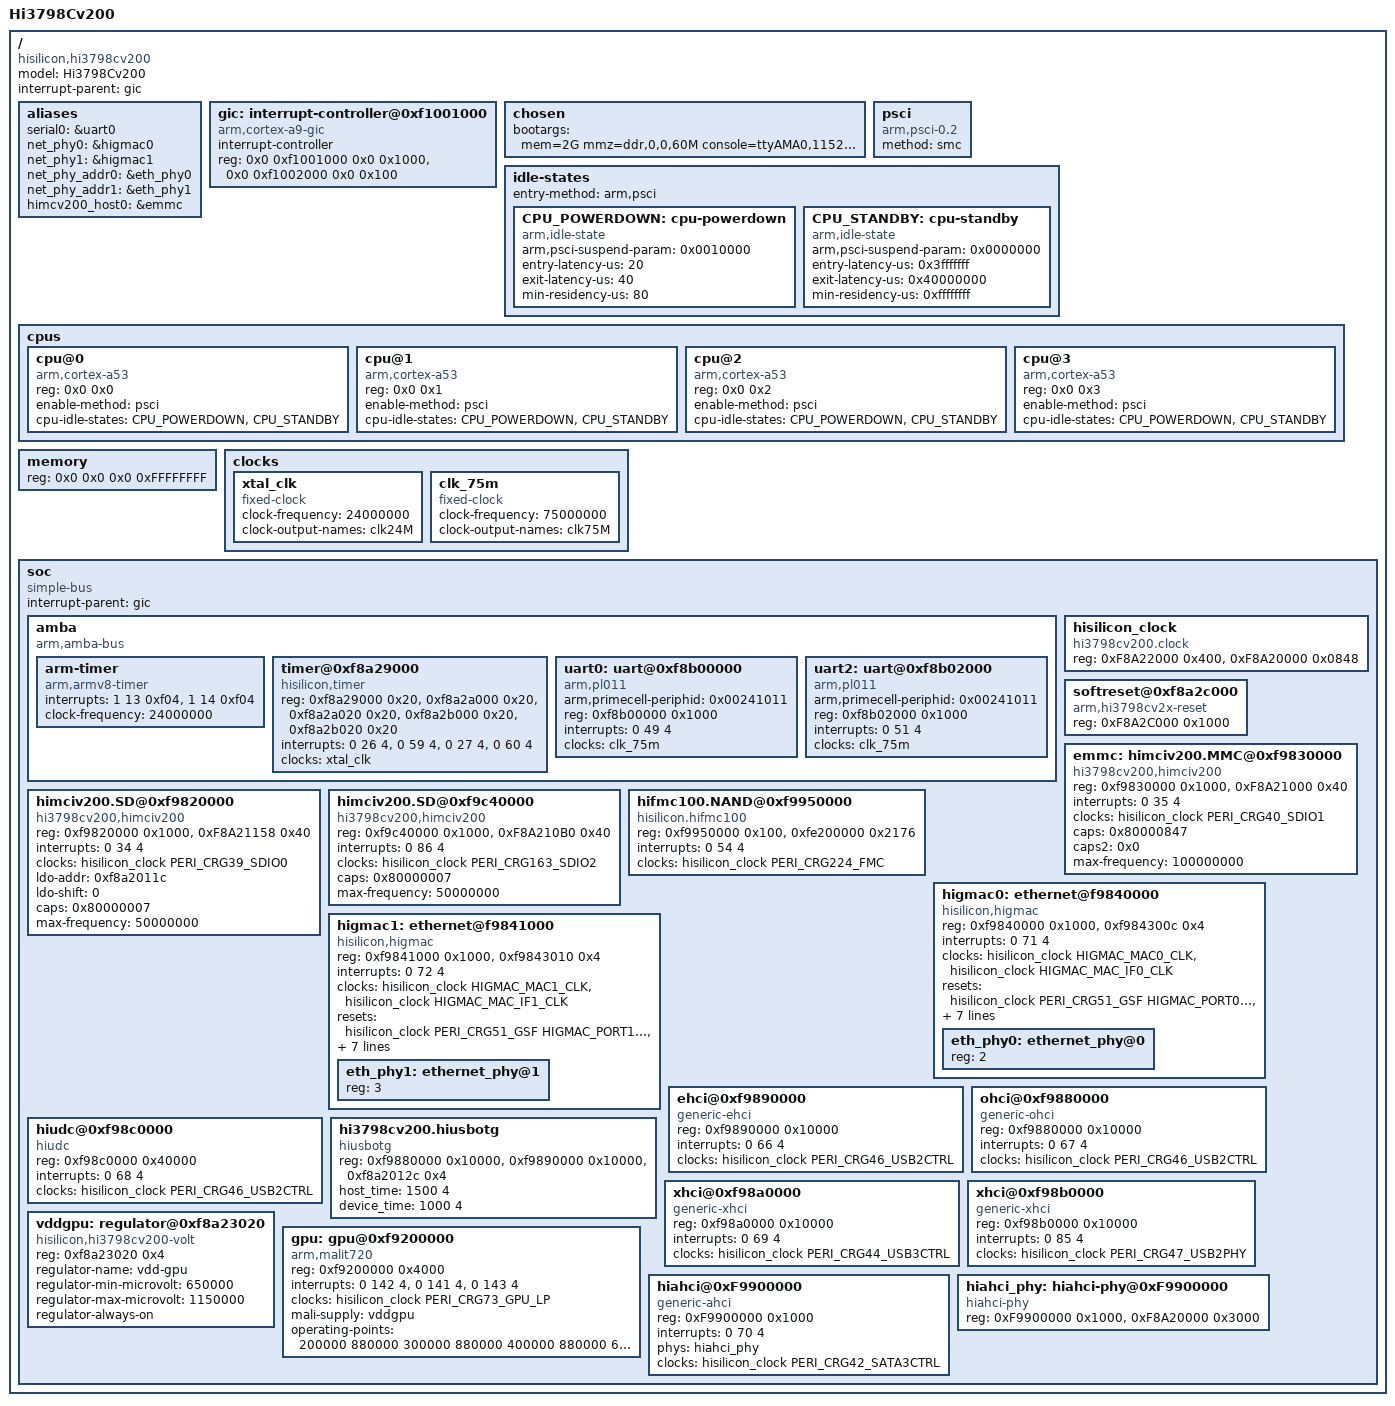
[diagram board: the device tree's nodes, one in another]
/*
 * Copyright (c) 2013 Linaro Ltd.
 * Copyright (c) 2013 Hisilicon Limited.
 *
 *  This program is free software; you can redistribute it and/or modify
 *  it under the terms of the GNU General Public License version 2 as
 *  publishhed by the Free Software Foundation.
 */

/dts-v1/;
/memreserve/ 0x00000000 0x00010000;
/* reserved for warmreset */
/memreserve/ 0xfff0000 0x00100000;
/* reserved for arm trustedfirmware */
/memreserve/ 0x4800000 0x00200000;

#include <dt-bindings/clock/hi3798cv200-clock.h>

/ {
	model = "Hi3798Cv200";
	compatible = "hisilicon,hi3798cv200";
	#address-cells = <2>;
	#size-cells = <2>;

	interrupt-parent = <&gic>;

	aliases {
		serial0 = &uart0;
		net_phy0 = &higmac0;
		net_phy1 = &higmac1;
		net_phy_addr0 = &eth_phy0;
		net_phy_addr1 = &eth_phy1;
		himcv200_host0 = &emmc;
	};

	gic: interrupt-controller@0xf1001000 {
		compatible = "arm,cortex-a9-gic"; /* TODO: maybe cortex-a53-gic in new kernel version */
		#interrupt-cells = <3>;
		#address-cells = <0>;
		interrupt-controller;
		/* gic dist base, gic cpu base */
		reg = <0x0 0xf1001000 0x0 0x1000>, <0x0 0xf1002000 0x0 0x100>;
	};

	chosen {
		bootargs = "mem=2G mmz=ddr,0,0,60M console=ttyAMA0,115200 root=/dev/mmcblk0p7 rootfstype=ext4 rootwait rw blkdevparts=mmcblk0:2M(boot),4M(baseparam),4M(pqparam),4M(logo),8M(trustedcore),16M(kernel),256M(rootfs),-(others) earlycon=pl011,0xf8b00000";
	};

	psci {
		compatible = "arm,psci-0.2";
		method = "smc";
	};

	idle-states {
		entry-method = "arm,psci";

		CPU_POWERDOWN: cpu-powerdown {
		       compatible = "arm,idle-state";
		       arm,psci-suspend-param = <0x0010000>;
		       entry-latency-us = <20>;
		       exit-latency-us = <40>;
		       min-residency-us = <80>;
		};
		CPU_STANDBY: cpu-standby {
		     compatible = "arm,idle-state";
		     arm,psci-suspend-param = <0x0000000>;
		     entry-latency-us = <0x3fffffff>;
		     exit-latency-us = <0x40000000>;
		     min-residency-us = <0xffffffff>;
		};
	};

	cpus {
		#address-cells = <2>;
		#size-cells = <0>;

		cpu@0 {
			compatible = "arm,cortex-a53";
			device_type = "cpu";
			reg = <0x0 0x0>;
			enable-method = "psci";
			cpu-idle-states = <&CPU_POWERDOWN &CPU_STANDBY>;
		};

		cpu@1 {
			compatible = "arm,cortex-a53";
			device_type = "cpu";
			reg = <0x0 0x1>;
			enable-method = "psci";
			cpu-idle-states = <&CPU_POWERDOWN &CPU_STANDBY>;
		};
		cpu@2 {
			compatible = "arm,cortex-a53";
			device_type = "cpu";
			reg = <0x0 0x2>;
			enable-method = "psci";
			cpu-idle-states = <&CPU_POWERDOWN &CPU_STANDBY>;
		};
		cpu@3 {
			compatible = "arm,cortex-a53";
			device_type = "cpu";
			reg = <0x0 0x3>;
			enable-method = "psci";
			cpu-idle-states = <&CPU_POWERDOWN &CPU_STANDBY>;
		};

	};

	memory {
		device_type = "memory";

		reg = <0x0 0x0 0x0 0xFFFFFFFF>;
	};

	clocks {
		xtal_clk: xtal_clk {
			compatible = "fixed-clock";
			#clock-cells = <0>;
			clock-frequency = <24000000>;
			clock-output-names = "clk24M";
		};

		clk_75m: clk_75m{
			compatible = "fixed-clock";
			#clock-cells = <0>;
			clock-frequency = <75000000>;
			clock-output-names = "clk75M";
		};
	};

	soc {
		#address-cells = <1>;
		#size-cells = <1>;
		compatible = "simple-bus";
		device_type = "soc";
		interrupt-parent = <&gic>;
		ranges = <0x0 0x00000000 0x0 0xffffffff>;

		amba {
			compatible = "arm,amba-bus";
			#address-cells = <1>;
			#size-cells = <1>;

			ranges;

			arm-timer {
				compatible = "arm,armv8-timer";
				interrupts = <1 13 0xf04>,
					     <1 14 0xf04>;
				clock-frequency = <24000000>;
			};

			/*
			 * Used for clocksource and local timer
			 */
			timer@0xf8a29000 {
				compatible = "hisilicon,timer";
				reg = <0xf8a29000 0x20>, /* clocksource */
				      <0xf8a2a000 0x20>, /* local timer for each cpu */
				      <0xf8a2a020 0x20>,
				      <0xf8a2b000 0x20>,
				      <0xf8a2b020 0x20>;
				interrupts = <0 26 4>, /* irq of local timer */
					     <0 59 4>,
					     <0 27 4>,
					     <0 60 4>;
				clocks = <&xtal_clk>;
				clock-names = "apb_pclk";
			};

			uart0: uart@0xf8b00000 {
				compatible = "arm,pl011", "arm,primecell";
				arm,primecell-periphid = <0x00241011>;
				reg = <0xf8b00000 0x1000>;
				interrupts = <0 49 4>;
				clocks = <&clk_75m>;
				clock-names = "apb_pclk";
			};

			uart2: uart@0xf8b02000 {
				compatible = "arm,pl011", "arm,primecell";
				arm,primecell-periphid = <0x00241011>;
				reg = <0xf8b02000 0x1000>;
				interrupts = <0 51 4>;
				clocks = <&clk_75m>;
				clock-names = "apb_pclk";
			};
		};

		hisilicon_clock: hisilicon_clock {
			compatible = "hi3798cv200.clock","hisilicon,clock-reset";
			reg = <0xF8A22000 0x400>, <0xF8A20000 0x0848>;
			#clock-cells = <1>;
			#reset-cells = <2>;
		};

		softreset@0xf8a2c000 {
			compatible = "arm,hi3798cv2x-reset";
			reg = <0xF8A2C000 0x1000>;
		};

		emmc: himciv200.MMC@0xf9830000 {
			compatible = "hi3798cv200,himciv200";
			reg = <0xf9830000 0x1000>,<0xF8A21000 0x40>;
			interrupts = <0 35 4>;

			clocks = <&hisilicon_clock PERI_CRG40_SDIO1>;
			clock-names = "clk";

			caps = <0x80000847>;
			caps2 = <0x0>;
			max-frequency = <100000000>;
			status = "okay";
		};

		himciv200.SD@0xf9820000 {
			compatible = "hi3798cv200,himciv200";
			reg = <0xf9820000 0x1000>,<0xF8A21158 0x40>;
			interrupts = <0 34 4>;

			clocks = <&hisilicon_clock PERI_CRG39_SDIO0>;
			clock-names = "clk";

			ldo-addr  = <0xf8a2011c>;
			ldo-shift = <0>;

			caps = <0x80000007>;
			max-frequency = <50000000>;
			status = "okay";
		};

		himciv200.SD@0xf9c40000 {
			compatible = "hi3798cv200,himciv200";
			reg = <0xf9c40000 0x1000>,<0xF8A210B0 0x40>;
			interrupts = <0 86 4>;

			clocks = <&hisilicon_clock PERI_CRG163_SDIO2>;
			clock-names = "clk";

			caps = <0x80000007>;
			max-frequency = <50000000>;
			status = "okay";
		};

		hifmc100.NAND@0xf9950000 {
			compatible = "hisilicon.hifmc100";
			reg = <0xf9950000 0x100>, <0xfe200000 0x2176>;
			interrupts = <0 54 4>;

			clocks = <&hisilicon_clock PERI_CRG224_FMC>;
			clock-names = "clk";
		};

		higmac0: ethernet@f9840000 {
			compatible = "hisilicon,higmac";
			reg = <0xf9840000 0x1000>,<0xf984300c 0x4>;
			interrupts = <0 71 4>;

			clocks = <&hisilicon_clock HIGMAC_MAC0_CLK>,
					<&hisilicon_clock HIGMAC_MAC_IF0_CLK>;
			clock-names = "higmac_clk",
					"macif_clk";

			resets = <&hisilicon_clock PERI_CRG51_GSF HIGMAC_PORT0_RST_BIT>,
					<&hisilicon_clock PERI_CRG51_GSF HIGMAC_MACIF0_RST_BIT>,
					<&hisilicon_clock PERI_CRG51_GSF HIGMAC_PHY0_RST_BIT>;
			reset-names = "port_reset",
					"macif_reset",
					"phy_reset";

			#address-cells = <1>;
			#size-cells = <0>;

			mac-address = [00 00 00 00 00 00];

			phy-handle = <&eth_phy0>;
			phy-mode = "mii";
			phy-gpio-base = <0>;
			phy-gpio-bit = <0>;

			eth_phy0: ethernet_phy@0 {
				reg = <2>;
			};
		};

		higmac1: ethernet@f9841000 {
			compatible = "hisilicon,higmac";
			reg = <0xf9841000 0x1000>,<0xf9843010 0x4>;
			interrupts = <0 72 4>;

			clocks = <&hisilicon_clock HIGMAC_MAC1_CLK>,
					<&hisilicon_clock HIGMAC_MAC_IF1_CLK>;
			clock-names = "higmac_clk",
					"macif_clk";

			resets = <&hisilicon_clock PERI_CRG51_GSF HIGMAC_PORT1_RST_BIT>,
					<&hisilicon_clock PERI_CRG51_GSF HIGMAC_MACIF1_RST_BIT>,
					<&hisilicon_clock PERI_CRG51_GSF HIGMAC_PHY1_RST_BIT>;
			reset-names = "port_reset",
					"macif_reset",
					"phy_reset";

			#address-cells = <1>;
			#size-cells = <0>;

			mac-address = [00 00 00 00 00 00];

			phy-handle = <&eth_phy1>;
			phy-mode = "rgmii";
			phy-gpio-base = <0>;
			phy-gpio-bit = <0>;

			eth_phy1: ethernet_phy@1{
				reg = <3>;
			};
		};

		ehci@0xf9890000 {
			compatible = "generic-ehci";
			reg = <0xf9890000 0x10000>;
			interrupts = <0 66 4>;

			clocks = <&hisilicon_clock PERI_CRG46_USB2CTRL>;
			clock-names = "clk";
		};

		ohci@0xf9880000 {
			compatible = "generic-ohci";
			reg = <0xf9880000 0x10000>;
			interrupts = <0 67 4>;

			clocks = <&hisilicon_clock PERI_CRG46_USB2CTRL>;
			clock-names = "clk";
		};

		hiudc@0xf98c0000 {
			compatible = "hiudc";
			reg = <0xf98c0000 0x40000>;
			interrupts = <0 68 4>;

			clocks = <&hisilicon_clock PERI_CRG46_USB2CTRL>;
			clock-names = "clk";
		};

		hi3798cv200.hiusbotg {
			compatible = "hiusbotg";
			reg = <0xf9880000 0x10000>,<0xf9890000 0x10000>,<0xf8a2012c 0x4>;
			host_time = <1500 4>;
			device_time = <1000 4>;
		};

		xhci@0xf98a0000 {
			compatible = "generic-xhci";
			reg = <0xf98a0000 0x10000>;
			interrupts = <0 69 4>;

			clocks = <&hisilicon_clock PERI_CRG44_USB3CTRL>;
			clock-names = "clk";
		};

		xhci@0xf98b0000 {
			compatible = "generic-xhci";
			reg = <0xf98b0000 0x10000>;
			interrupts = <0 85 4>;

			clocks = <&hisilicon_clock PERI_CRG47_USB2PHY>;
			clock-names = "clk";
			status = "okay";
		};

		vddgpu: regulator@0xf8a23020 {
			compatible = "hisilicon,hi3798cv200-volt";
			reg = <0xf8a23020 0x4>;
			reg-names = "base-address";
			regulator-name = "vdd-gpu";
			regulator-min-microvolt = <650000>;
			regulator-max-microvolt = <1150000>;
			regulator-always-on;
		};

		gpu:gpu@0xf9200000 {
			compatible = "arm,malit720", "arm,mali", "arm,mali-midgard";
			reg = <0xf9200000 0x4000>;
			interrupts = <0 142 4>, <0 141 4>, <0 143 4>;
			interrupt-names = "JOB", "MMU", "GPU";
			clocks = <&hisilicon_clock PERI_CRG73_GPU_LP>;
			clock-names = "clk_mali";
			mali-supply = <&vddgpu>;
			operating-points = <
			200000 880000
			300000 880000
			400000 880000
			600000 1120000>;
		};
		hiahci@0xF9900000 {
			compatible = "generic-ahci";
			reg = <0xF9900000 0x1000>;
			interrupts = <0 70 4>;

			phys = <&hiahci_phy>;
			phy-names = "sata-phy";

			clocks = <&hisilicon_clock PERI_CRG42_SATA3CTRL>;
			clock-names = "clk";
			status = "okay";
		};
		hiahci_phy: hiahci-phy@0xF9900000 {
			compatible = "hiahci-phy";
			reg = <0xF9900000 0x1000>,<0xF8A20000 0x3000>;
			#phy-cells = <0>;
		};

	};
};
